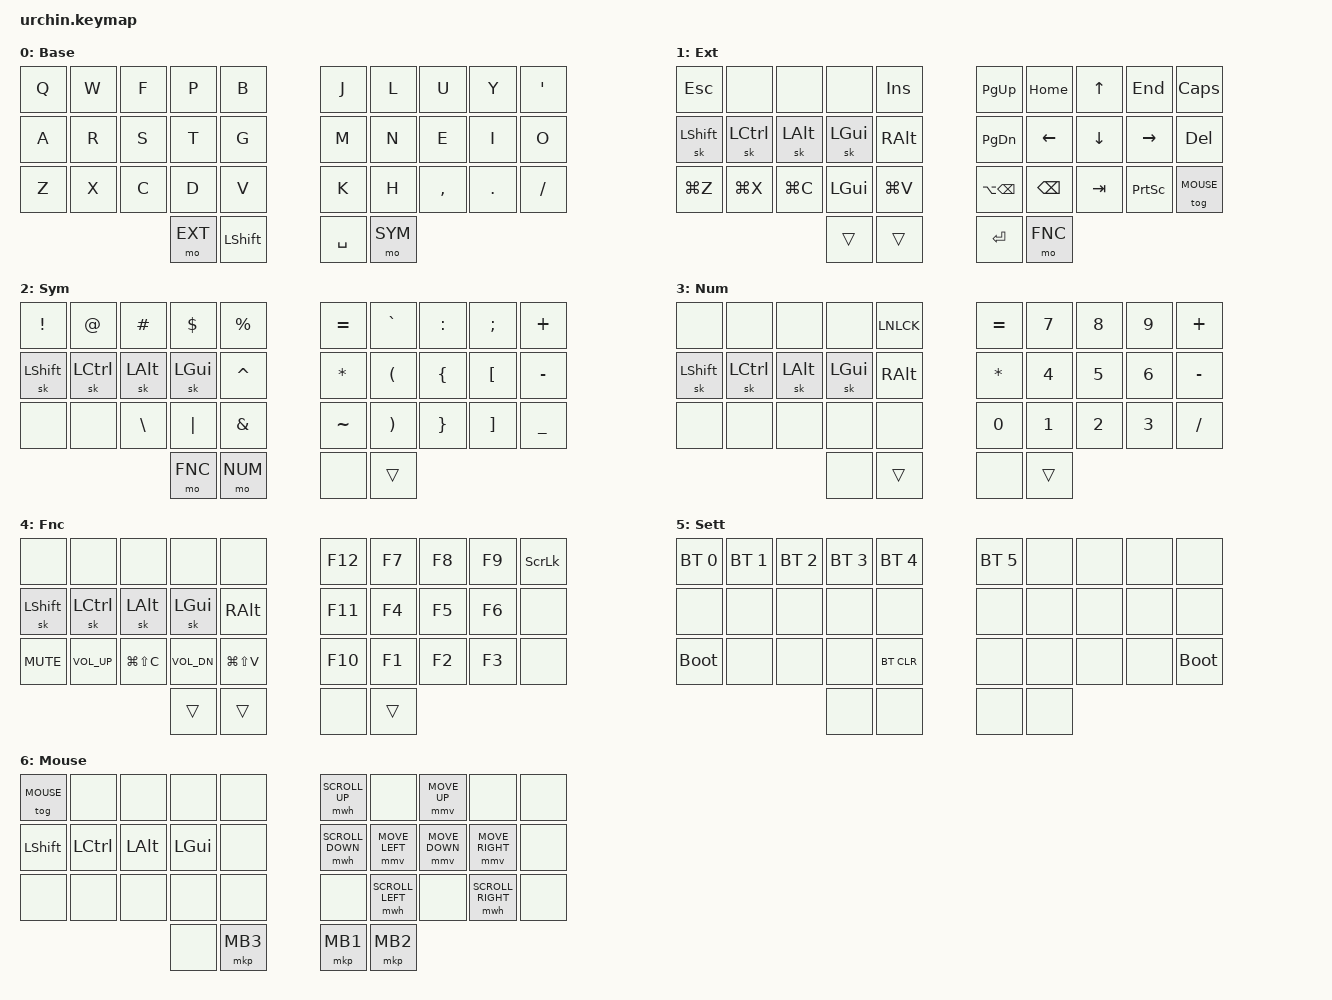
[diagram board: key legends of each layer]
#include <behaviors.dtsi>
#include <dt-bindings/zmk/keys.h>
#include <dt-bindings/zmk/bt.h>
#include <dt-bindings/zmk/outputs.h>
#include <dt-bindings/zmk/mouse.h>

/* Layers */

#define BASE 0
#define EXT 1
#define SYM 2
#define NUM 3
#define FNC 4
#define SETTINGS 5
#define MOUSE 6

/* Mouse */

&mmv {
  acceleration-exponent = <1>;      // 1
  time-to-max-speed-ms = <1500>;    // 40
  delay-ms = <0>;                   // 0
};

&mwh {
  acceleration-exponent = <1>;      // 0
  time-to-max-speed-ms = <5000>;    // 40
  delay-ms = <0>;                   // 10
};

#define U_MOUSE_MOVE_MAX 1250       // 600
#define U_MOUSE_SCROLL_MAX 100      // 10

#undef MOVE_UP
#undef MOVE_DOWN
#undef MOVE_LEFT
#undef MOVE_RIGHT
#define MOVE_UP MOVE_VERT(-U_MOUSE_MOVE_MAX)
#define MOVE_DOWN MOVE_VERT(U_MOUSE_MOVE_MAX)
#define MOVE_LEFT MOVE_HOR(-U_MOUSE_MOVE_MAX)
#define MOVE_RIGHT MOVE_HOR(U_MOUSE_MOVE_MAX)

#undef SCROLL_UP
#undef SCROLL_DOWN
#undef SCROLL_LEFT
#undef SCROLL_RIGHT
#define SCROLL_UP SCROLL_VERT(U_MOUSE_SCROLL_MAX)
#define SCROLL_DOWN SCROLL_VERT(-U_MOUSE_SCROLL_MAX)
#define SCROLL_LEFT SCROLL_HOR(-U_MOUSE_SCROLL_MAX)
#define SCROLL_RIGHT SCROLL_HOR(U_MOUSE_SCROLL_MAX)

/* Global settings */

&sk {
    // don't release mods on other mods presses
    ignore-modifiers;
};

/ {
    behaviors {
        // Enables holding the first mod-tap key
        // by performing a tap-release-hold sequence.
        // To use it: "&qt KEYCODE1 KEYCODE2"
        qt: quick_tap {
            compatible = "zmk,behavior-hold-tap";
            label = "QUICK_TAP";
            #binding-cells = <2>;
            flavor = "hold-preferred";
            tapping-term-ms = <200>;
            quick-tap-ms = <200>;
            bindings = <&kp>, <&kp>;
        };
    };

    combos {
        compatible = "zmk,combos";

        // internal-left & external-right thumb keys
        combo_num {
            timeout-ms = <200>;
            key-positions = <31 33>;
            bindings = <&mo NUM>;
        };
        // external-left & external-right thumb keys
        combo_fnc {
            timeout-ms = <200>;
            key-positions = <30 33>;
            bindings = <&mo FNC>;
        };
        // both left thumb keys
        combo_settings {
            timeout-ms = <200>;
            key-positions = <30 31>;
            bindings = <&mo SETTINGS>;
        };
    };

    keymap {
        compatible = "zmk,keymap";

        default_layer {
            label = "Base";
            bindings = <
// ╭───────────┬───────────┬───────────┬───────────┬───────────╮        ╭───────────┬───────────┬───────────┬───────────┬───────────╮
    &kp Q       &kp W       &kp F       &kp P       &kp B                &kp J       &kp L       &kp U       &kp Y       &kp SQT
// ├───────────┼───────────┼───────────┼───────────┼───────────┤        ├───────────┼───────────┼───────────┼───────────┼───────────┤
    &kp A       &kp R       &kp S       &kp T       &kp G                &kp M       &kp N       &kp E       &kp I       &kp O
// ├───────────┼───────────┼───────────┼───────────┼───────────┤        ├───────────┼───────────┼───────────┼───────────┼───────────┤
    &kp Z       &kp X       &kp C       &kp D       &kp V                &kp K       &kp H       &kp COMMA   &kp DOT     &kp FSLH
// ╰───────────┴───────────┴───────────┼───────────┼───────────┤        ├───────────┼───────────┼───────────┴───────────┴───────────╯
                                        &mo EXT     &kp LSHFT            &kp SPACE   &mo SYM
//                                     ╰───────────┴───────────╯        ╰───────────┴───────────╯
            >;
        };

        ext_layer {
            label = "Ext";
            bindings = <
// ╭───────────┬───────────┬───────────┬───────────┬───────────╮        ╭───────────┬───────────┬───────────┬───────────┬───────────╮
    &kp ESC     &none       &none       &none       &kp INS              &kp PG_UP   &kp HOME    &kp UP      &kp END     &kp CAPS
// ├───────────┼───────────┼───────────┼───────────┼───────────┤        ├───────────┼───────────┼───────────┼───────────┼───────────┤
    &sk LSHFT   &sk LCTRL   &sk LALT    &sk LGUI    &kp RALT             &kp PG_DN   &kp LEFT    &kp DOWN    &kp RIGHT   &kp DEL
// ├───────────┼───────────┼───────────┼───────────┼───────────┤        ├───────────┼───────────┼───────────┼───────────┼───────────┤
    &kp LG(Z)   &kp LG(X)   &kp LG(C)   &kp LGUI    &kp LG(V)           &kp LA(BSPC) &kp BSPC    &kp TAB     &kp PSCRN   &tog MOUSE
// ╰───────────┴───────────┴───────────┼───────────┼───────────┤        ├───────────┼───────────┼───────────┴───────────┴───────────╯
                                        &trans      &trans               &kp ENTER   &mo FNC
//                                     ╰───────────┴───────────╯        ╰───────────┴───────────╯
            >;
        };

        sym_layer {
            label = "Sym";
            bindings = <
// ╭───────────┬───────────┬───────────┬───────────┬───────────╮        ╭───────────┬───────────┬───────────┬───────────┬───────────╮
    &kp EXCL    &kp AT      &kp HASH    &kp DOLLAR  &kp PERCENT          &kp EQUAL   &kp GRAVE   &kp COLON   &kp SEMI    &kp PLUS
// ├───────────┼───────────┼───────────┼───────────┼───────────┤        ├───────────┼───────────┼───────────┼───────────┼───────────┤
    &sk LSHFT   &sk LCTRL   &sk LALT    &sk LGUI    &kp CARET            &kp ASTRK   &kp LPAR    &kp LBRC    &kp LBKT    &kp MINUS
// ├───────────┼───────────┼───────────┼───────────┼───────────┤        ├───────────┼───────────┼───────────┼───────────┼───────────┤
    &none       &none       &kp BSLH    &kp PIPE    &kp AMPS             &kp TILDE &kp RPAR      &kp RBRC    &kp RBKT    &kp UNDER
// ╰───────────┴───────────┴───────────┼───────────┼───────────┤        ├───────────┼───────────┼───────────┴───────────┴───────────╯
                                        &mo FNC     &mo NUM              &none       &trans
//                                     ╰───────────┴───────────╯        ╰───────────┴───────────╯
            >;
        };

        num_layer {
            label = "Num";
            bindings = <
// ╭───────────┬───────────┬───────────┬───────────┬───────────╮        ╭───────────┬───────────┬───────────┬───────────┬───────────╮
    &none       &none       &none       &none       &kp LNLCK            &kp EQUAL   &kp N7      &kp N8      &kp N9      &kp PLUS
// ├───────────┼───────────┼───────────┼───────────┼───────────┤        ├───────────┼───────────┼───────────┼───────────┼───────────┤
    &sk LSHFT   &sk LCTRL   &sk LALT    &sk LGUI    &kp RALT             &kp ASTRK   &kp N4      &kp N5      &kp N6      &kp MINUS
// ├───────────┼───────────┼───────────┼───────────┼───────────┤        ├───────────┼───────────┼───────────┼───────────┼───────────┤
    &none       &none       &none       &none       &none                &kp N0      &kp N1      &kp N2      &kp N3      &kp FSLH
// ╰───────────┴───────────┴───────────┼───────────┼───────────┤        ├───────────┼───────────┼───────────┴───────────┴───────────╯
                                        &none       &trans               &none       &trans
//                                     ╰───────────┴───────────╯        ╰───────────┴───────────╯
            >;
        };

        fnc_layer {
            label = "Fnc";
            bindings = <
// ╭───────────┬───────────┬───────────┬───────────┬───────────╮        ╭───────────┬───────────┬───────────┬───────────┬───────────╮
    &none       &none       &none       &none       &none                &kp F12     &kp F7      &kp F8      &kp F9      &kp SLCK
// ├───────────┼───────────┼───────────┼───────────┼───────────┤        ├───────────┼───────────┼───────────┼───────────┼───────────┤
    &sk LSHFT   &sk LCTRL   &sk LALT    &sk LGUI    &kp RALT             &kp F11     &kp F4      &kp F5      &kp F6      &none
// ├───────────┼───────────┼───────────┼───────────┼───────────┤        ├───────────┼───────────┼───────────┼───────────┼───────────┤
    &kp C_MUTE  &kp C_VOL_UP &kp LG(LS(C)) &kp C_VOL_DN &kp LG(LS(V))    &kp F10     &kp F1      &kp F2      &kp F3      &none
// ╰───────────┴───────────┴───────────┼───────────┼───────────┤        ├───────────┼───────────┼───────────┴───────────┴───────────╯
                                        &trans      &trans               &none       &trans
//                                     ╰───────────┴───────────╯        ╰───────────┴───────────╯
            >;
        };

        settings_layer {
                label = "Sett";
                bindings = <
// ╭───────────┬───────────┬───────────┬───────────┬───────────╮        ╭───────────┬───────────┬───────────┬───────────┬───────────╮
   &bt BT_SEL 0 &bt BT_SEL 1 &bt BT_SEL 2 &bt BT_SEL 3 &bt BT_SEL 4     &bt BT_SEL 5 &none       &none       &none       &none
// ├───────────┼───────────┼───────────┼───────────┼───────────┤        ├───────────┼───────────┼───────────┼───────────┼───────────┤
    &none       &none       &none       &none       &none                &none       &none       &none       &none       &none
// ├───────────┼───────────┼───────────┼───────────┼───────────┤        ├───────────┼───────────┼───────────┼───────────┼───────────┤
    &bootloader &none       &none       &none       &bt BT_CLR           &none       &none       &none       &none       &bootloader
// ╰───────────┴───────────┴───────────┼───────────┼───────────┤        ├───────────┼───────────┼───────────┴───────────┴───────────╯
                                        &none       &none                &none       &none
//                                     ╰───────────┴───────────╯        ╰───────────┴───────────╯
                >;
        };

        mouse_layer {
                label = "Mouse";
                bindings = <
// ╭───────────┬───────────┬───────────┬───────────┬───────────╮        ╭───────────┬───────────┬───────────┬───────────┬───────────╮
    &tog MOUSE  &none       &none       &none       &none          &mwh SCROLL_UP    &none      &mmv MOVE_UP &none       &none
// ├───────────┼───────────┼───────────┼───────────┼───────────┤        ├───────────┼───────────┼───────────┼───────────┼───────────┤
    &kp LSHFT   &kp LCTRL   &kp LALT    &kp LGUI    &none          &mwh SCROLL_DOWN &mmv MOVE_LEFT &mmv MOVE_DOWN &mmv MOVE_RIGHT &none
// ├───────────┼───────────┼───────────┼───────────┼───────────┤        ├───────────┼───────────┼───────────┼───────────┼───────────┤
    &none       &none       &none       &none       &none                &none      &mwh SCROLL_LEFT &none  &mwh SCROLL_RIGHT &none
// ╰───────────┴───────────┴───────────┼───────────┼───────────┤        ├───────────┼───────────┼───────────┴───────────┴───────────╯
                                        &none       &mkp MB3             &mkp MB1    &mkp MB2
//                                     ╰───────────┴───────────╯        ╰───────────┴───────────╯
                >;
        };
    };
};
